# ADuCM320 register map
Vendor: Analog Devices Inc.; Series: ARMCM3; File version: 1.1
Cortex-M3 Microcontroller Device
CPU: CM3 r2p1, little endian, no MPU, no FPU, 3 interrupt priority bits
Registers are 16-bit, read-write, no defined reset value unless marked. A register's access mark holds for its fields unless they carry their own. Offsets are from the block's base; lines under a group give offsets from that group; [hi:lo] are bit positions; {n}, {i} and the like mark numbered series; 'fields as' and 'values as' point back to an identical list; <NAME> marks a mode.

## Memory map
0x40000000 Timer0 size 0x20 — General purpose timer 0
0x40000400 Timer1 size 0x20 — General purpose timer 1
0x40000800 Timer2 size 0x20 — General purpose timer 2
0x40002024 ID size 0x4 — ChipID
0x40002400 PWRCTL size 0x8 — Power management
0x40002408 RESET size 0x40
0x40002420 INTERRUPT size 0x14 — External interrupts
0x40002500 WUT size 0x44 — Wake up Timer
0x40002580 WDT size 0x1C — Watchdog Timer
0x40003000 I2C0 size 0x58 — I2C0 Master/Slave
0x40003400 I2C1 size 0x58 — I2C1 Master/Slave
0x40005000 UART size 0x34
0x40005800 PLA size 0x1B4 — Programmable Logic Array
0x40005C00 MDIO size 0x24 — MDIO Interface
0x40010000 DMA size 0xFE4 — Direct Memory Access
0x40018000 FEE size 0xE8 — Flash Controller
0x40020000 GPIO0 size 0x28 — General Purpose Input Output 0
0x40020040 GPIO1 size 0x28 — General Purpose Input Output 1
0x40020080 GPIO2 size 0x28 — General Purpose Input Output 2
0x400200C0 GPIO3 size 0x28 — General Purpose Input Output 3
0x40020100 GPIO4 size 0x28 — General Purpose Input Output 4
0x40020240 GPIO5 size 0x28 — General Purpose Input Output 5
0x40024000 PWM size 0x50 — Pulse Width Modulation
0x40028000 CLKCTL size 0x1C — Clock Gating and Other Settings
0x4002C000 SPI0 size 0x1C — Serial Peripheral Interface 0
0x40030000 SPI1 size 0x1C — Serial Peripheral Interface 1
0x40081400 InBuf size 0x2014 — Input Buffer
0x40082170 ADC size 0x3F7C — Analog to Digital converter
0x40082400 VDAC size 0x4024
0x40082C30 LV size 0x4 — Low voltage die ID
0x40082C34 LV_RST size 0x4 — Low voltage die reset configuration
0x40083004 LV_INT size 0xC — Low voltage die interrupt configuration
0x40086800 IDAC size 0x20
0x40087800 AFE size 0x3C — Analog
0xE000E000 NVIC size 0x1001 — Nested Vectored Interrupt Controller

## Interrupts
0 WUT
{n+1} EINT{n} (INTERRUPT) (n=0..8)
10 WDT
13 LVD0 (ADC)
14 MDIO
15 TIMER0 (Timer0)
16 TIMER1 (Timer1)
17 FLASH (FEE)
18 UART
19 SPI0
20 SPI1
21 I2C0S (I2C0)
22 I2C0M (I2C0)
23 PLA0 (PLA)
24 PLA1 (PLA)
25 DMA_ERR (DMA)
26 DMA_SPI0_TX (DMA)
27 DMA_SPI0_RX (DMA)
28 DMA_SPI1_TX (DMA)
29 DMA_SPI1_RX (DMA)
30 DMA_UART_TX (DMA)
31 DMA_UART_RX (DMA)
32 DMA_I2C0S_TX (DMA)
33 DMA_I2C0S_RX (DMA)
34 DMA_I2C0M (DMA)
35 DMA_I2C1S_TX (DMA)
36 DMA_I2C1S_RX (DMA)
37 DMA_I2C1M (DMA)
38 DMA_ADC (DMA)
39 DMA_FLASH (DMA)
44 I2C1S (I2C1)
45 I2C1M (I2C1)
46 PLA2 (PLA)
47 PLA3 (PLA)
48 TIMER2 (Timer2)
49 LVD1 (ADC)
50 PWM_TRIP (PWM)
51 PWM_PAIR0 (PWM)
52 PWM_PAIR1 (PWM)
53 PWM_PAIR2 (PWM)
54 PWM_PAIR3 (PWM)

## Timer0 — General purpose timer 0
Base 0x40000000
0x00 T0LD — 16-bit load value register
  [15:0] LOAD range 0x00000000..0x0000FFFF — Load value
0x04 T0VAL ro — 16-bit timer value register
  [15:0] VAL range 0x00000000..0x0000FFFF — Current count
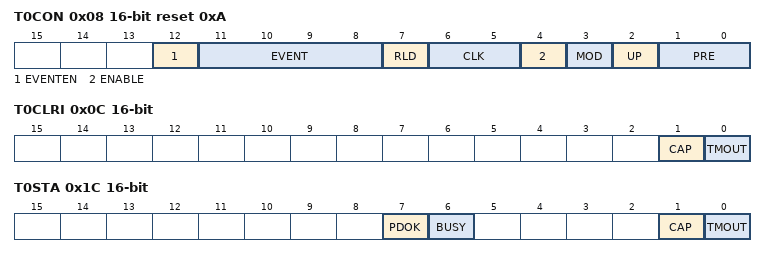
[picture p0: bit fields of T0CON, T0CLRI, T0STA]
0x08 T0CON reset 0xA (reset mask 0x0) — Control register
  [12] EVENTEN — Event select
    0=DIS (Events will not be captured); 1=EN (Events will be captured)
  [11:8] EVENT range 0x00000000..0x0000000F — Event select range
  [7] RLD — Reload control
    1=EN (Resets the up/down counter when TCLRI[0] is set); 0=DIS (Up/Down counter is only reset on a timeout event)
  [6:5] CLK — Clock select
    0=PCLK; 1=HCLK; 2=LFOSC (32 KHz OSC); 3=HFXTAL (16 MHz OSC or XTAL (Dependent on CLKCON0.11))
  [4] ENABLE — Timer enable
    0=DIS (Timer is disabled (default)); 1=EN (Timer is enabled)
  [3] MOD — Timer mode
    0=FREERUN (Timer runs in free running mode); 1=PERIODIC (Timer runs in periodic mode (default))
  [2] UP — Count up
    0=DIS (Timer is set to count down (default)); 1=EN (Timer is set to count up)
  [1:0] PRE — Prescaler
    0=DIV1 (source_clock / [1 or 4]); 1=DIV16 (source_clock / 16); 2=DIV256 (source_clock / 256); 3=DIV32768 (source_clock / 32,768)
0x0C T0CLRI wo — Clear interrupt register
  [1] CAP — Clear captured event interrupt
    1=CLR (Clear the capture event interrupt)
  [0] TMOUT — Clear timeout interrupt
    1=CLR (Clears the timeout interrupt)
0x10 T0CAP ro — Capture register
  [15:0] CAP range 0x00000000..0x0000FFFF — 16-bit captured value
0x1C T0STA ro — Status register
  [7] PDOK — TCLRI synchronization
    0=CLR (The interrupt is cleared in the timer clock domain); 1=SET (TCLRI[0] is being updated in the timer clock domain)
  [6] BUSY — Timer Busy
    0=CLR (Timer ready to receive commands to TCON); 1=SET (Timer not ready to receive commands to TCON)
  [1] CAP — Capture event pending
    0=CLR (No capture event is pending); 1=SET (A capture event is pending)
  [0] TMOUT — Timeout event occurred
    0=CLR (No timeout event has occurred); 1=SET (A timeout event has occurred)

## Licence text in the file
THIS SOFTWARE IS PROVIDED BY ANALOG DEVICES INC. ``AS IS'' AND ANY EXPRESS OR IMPLIED WARRANTIES, INCLUDING, BUT NOT LIMITED TO, THE IMPLIED WARRANTIES OF MERCHANTABILITY, FITNESS FOR A PARTICULAR PURPOSE, OR NON-INFRINGEMENT, ARE DISCLAIMED. IN NO EVENT SHALL ANALOG DEVICES INC. BE LIABLE FOR ANY DIRECT, INDIRECT, INCIDENTAL, SPECIAL, EXEMPLARY, OR CONSEQUENTIAL DAMAGES ARISING IN ANY WAY OUT OF THE USE OF THIS SOFTWARE, EVEN IF ADVISED OF THE POSSIBILITY OF SUCH DAMAGE. YOU ASSUME ANY AND ALL RISK FROM THE USE OF THIS CODE OR SUPPORT FILE. IT IS THE RESPONSIBILITY OF THE PERSON INTEGRATING THIS CODE INTO AN APPLICATION TO ENSURE THAT THE RESULTING APPLICATION PERFORMS AS REQUIRED AND IS SAFE.

## Notices in the file
Copyright (C) 2014 Analog Devices Inc. All rights reserved. Purpose:
System Viewer Description (SVD) Schema Version 1.1) for the ADuCM320 device.
